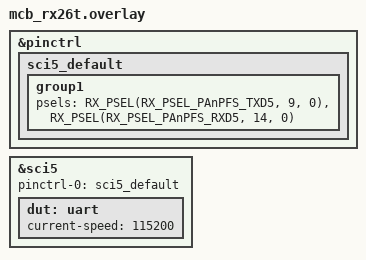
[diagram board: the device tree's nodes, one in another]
/*
 * Copyright (c) 2025 Renesas Electronics Corporation
 *
 * SPDX-License-Identifier: Apache-2.0
 */

&pinctrl {
	sci5_default: sci5_default {
		group1 {
			psels = <RX_PSEL(RX_PSEL_PAnPFS_TXD5, 9, 0)>,
				<RX_PSEL(RX_PSEL_PAnPFS_RXD5, 14, 0)>;
		};
	};
};

&sci5 {
	pinctrl-0 = <&sci5_default>;
	pinctrl-names = "default";
	status = "okay";

	dut: uart {
		current-speed = <115200>;
		status = "okay";
	};
};
